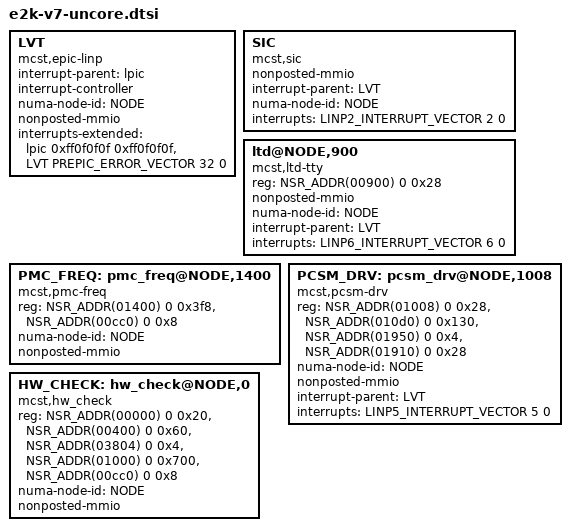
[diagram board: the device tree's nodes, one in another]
/*
 * SPDX-License-Identifier: GPL-2.0
 * Copyright (c) 2023 MCST
 */

#include <dt-bindings/interrupt-controller/irq.h>
#include "apic-vectors.h"

	LVT: LVT {
		compatible = "mcst,epic-linp";
		interrupt-parent = <&lpic>;
		interrupt-controller;
		numa-node-id = <NODE>;
		nonposted-mmio;
		interrupts-extended = <&lpic 0xff0f0f0f 0xff0f0f0f>, /*stub for linux to find parent*/
					 <&LVT PREPIC_ERROR_VECTOR 32 0>;
		interrupt-names = "stub", "PREPIC error interrupts";
		#interrupt-cells = <3>;
	};
	SIC {
		compatible = "mcst,sic";
		/* reg = <0x1 0x10000000 0 0x100000>; not used */
		nonposted-mmio;
		interrupt-parent = <&LVT>;
		numa-node-id = <NODE>;
		interrupts = <LINP2_INTERRUPT_VECTOR 2 0>;
	};
	ltd@NODE,900 {
		compatible = "mcst,ltd-tty";
		reg = <NSR_ADDR(00900) 0 0x28>;
		nonposted-mmio;
		numa-node-id = <NODE>;
		interrupt-parent = <&LVT>;
		interrupts = <LINP6_INTERRUPT_VECTOR 6 0>;
	};
	PMC_FREQ: pmc_freq@NODE,1400 {
		compatible = "mcst,pmc-freq";
		reg = <NSR_ADDR(01400) 0 0x3f8>, <NSR_ADDR(00cc0) 0 0x8>;
		numa-node-id = <NODE>;
		nonposted-mmio;
	};
	PCSM_DRV: pcsm_drv@NODE,1008 {
		compatible = "mcst,pcsm-drv";
		reg = <NSR_ADDR(01008) 0 0x28>,
		      <NSR_ADDR(010d0) 0 0x130>,
		      <NSR_ADDR(01950) 0 0x4>,
		      <NSR_ADDR(01910) 0 0x28>;
		numa-node-id = <NODE>;
		nonposted-mmio;
		interrupt-parent = <&LVT>;
		interrupts = <LINP5_INTERRUPT_VECTOR 5 0>;
		interrupt-names = "PCS interrupts";
	};
	HW_CHECK: hw_check@NODE,0 {
		compatible = "mcst,hw_check";
		reg = <NSR_ADDR(00000) 0 0x20>,
		      <NSR_ADDR(00400) 0 0x60>,
		      <NSR_ADDR(03804) 0 0x4>,
		      <NSR_ADDR(01000) 0 0x700>,
		      <NSR_ADDR(00cc0) 0 0x8>;
		numa-node-id = <NODE>;
		nonposted-mmio;
	};
